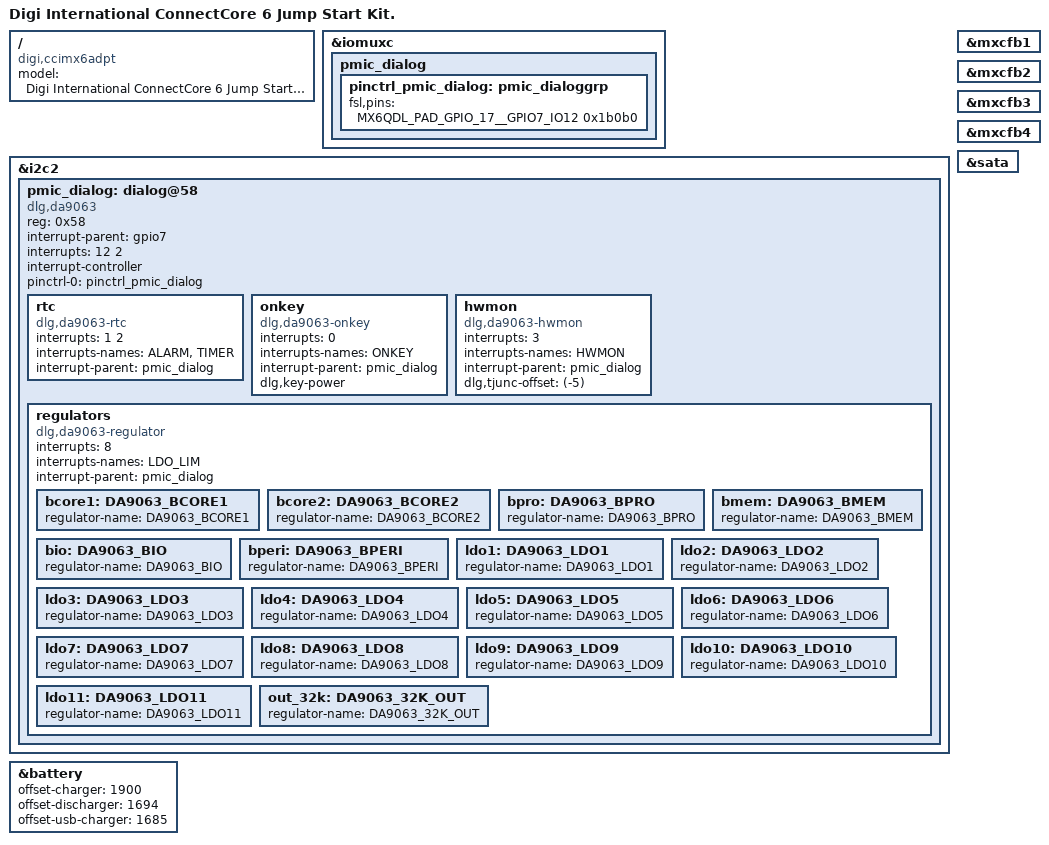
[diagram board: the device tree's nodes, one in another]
/*
 * Copyright 2013 Digi International, Inc.
 * Copyright 2012 Freescale Semiconductor, Inc.
 * Copyright 2011 Linaro Ltd.
 *
 * The code contained herein is licensed under the GNU General Public
 * License. You may obtain a copy of the GNU General Public License
 * Version 2 or later at the following locations:
 *
 * http://www.opensource.org/licenses/gpl-license.html
 * http://www.gnu.org/copyleft/gpl.html
 */

/dts-v1/;

#include "imx6q.dtsi"
#include "imx6-ccimx6qdladpt.dtsi"

/ {
	model = "Digi International ConnectCore 6 Jump Start Kit.";
	compatible = "digi,ccimx6adpt", "fsl,imx6q";
};

&iomuxc {
	pmic_dialog {
		pinctrl_pmic_dialog: pmic_dialoggrp {
			fsl,pins = <
				MX6QDL_PAD_GPIO_17__GPIO7_IO12 0x1b0b0
			>;
		};
	};
};

&i2c2 {
	pmic_dialog: dialog@58 {
		compatible = "dlg,da9063";
		reg = <0x58>;
		interrupt-parent = <&gpio7>;
		interrupts = <12 2>;
		interrupt-controller;
		#interrupt-cells = <1>;
		pinctrl-names = "default";
		pinctrl-0 = <&pinctrl_pmic_dialog>;

		rtc {
			compatible = "dlg,da9063-rtc";
			interrupts = <1 2>;
			interrupts-names = "ALARM" , "TIMER";
			interrupt-parent = <&pmic_dialog>;
		};

		onkey {
			compatible = "dlg,da9063-onkey";
			interrupts = <0>;
			interrupts-names = "ONKEY";
			interrupt-parent = <&pmic_dialog>;
			dlg,key-power;
		};

		hwmon {
			compatible = "dlg,da9063-hwmon";
			interrupts = <3>;
			interrupts-names = "HWMON";
			interrupt-parent = <&pmic_dialog>;
			dlg,tjunc-offset = <(-5)>;
		};

		/* For DA9063 revision AD */
		regulators {
			compatible = "dlg,da9063-regulator";
			/*dlg,bcores_merged;*/
			/*dlg,bmem_bio_merged;*/
			interrupts = <8>;
			interrupts-names = "LDO_LIM";
			interrupt-parent = <&pmic_dialog>;


			bcore1: DA9063_BCORE1 {
				regulator-name = "DA9063_BCORE1";
			};

			bcore2: DA9063_BCORE2 {
				regulator-name = "DA9063_BCORE2";
			};

			bpro: DA9063_BPRO {
				regulator-name = "DA9063_BPRO";
			};

			bmem: DA9063_BMEM {
				regulator-name = "DA9063_BMEM";
			};

			bio: DA9063_BIO {
				regulator-name = "DA9063_BIO";
			};

			bperi: DA9063_BPERI {
				regulator-name = "DA9063_BPERI";
			};

			/*
			bcores_merged: DA9063_BCORES_MERGED {
				regulator-name = "DA9063_BCORES_MERGED";
			};

			bmem_bio_merged: DA9063_BMEM_BIO_MERGED {
				regulator-name = "DA9063_BMEM_BIO_MERGED";
			};
			*/

			ldo1: DA9063_LDO1 {
				regulator-name = "DA9063_LDO1";
			};

			ldo2: DA9063_LDO2 {
				regulator-name = "DA9063_LDO2";
			};

			ldo3: DA9063_LDO3 {
				regulator-name = "DA9063_LDO3";
			};

			ldo4: DA9063_LDO4 {
				regulator-name = "DA9063_LDO4";
			};

			ldo5: DA9063_LDO5 {
				regulator-name = "DA9063_LDO5";
			};

			ldo6: DA9063_LDO6 {
				regulator-name = "DA9063_LDO6";
			};

			ldo7: DA9063_LDO7 {
				regulator-name = "DA9063_LDO7";
			};

			ldo8: DA9063_LDO8 {
				regulator-name = "DA9063_LDO8";
			};

			ldo9: DA9063_LDO9 {
				regulator-name = "DA9063_LDO9";
			};

			ldo10: DA9063_LDO10 {
				regulator-name = "DA9063_LDO10";
			};

			ldo11: DA9063_LDO11 {
				regulator-name = "DA9063_LDO11";
			};

			out_32k: DA9063_32K_OUT {
				regulator-name = "DA9063_32K_OUT";
			};
		};
	};
};

&battery {
	offset-charger = <1900>;
	offset-discharger = <1694>;
	offset-usb-charger = <1685>;
};

&mxcfb1 {
	status = "okay";
};

&mxcfb2 {
	status = "okay";
};

&mxcfb3 {
	status = "okay";
};

&mxcfb4 {
	status = "okay";
};

&sata {
	status = "okay";
};
